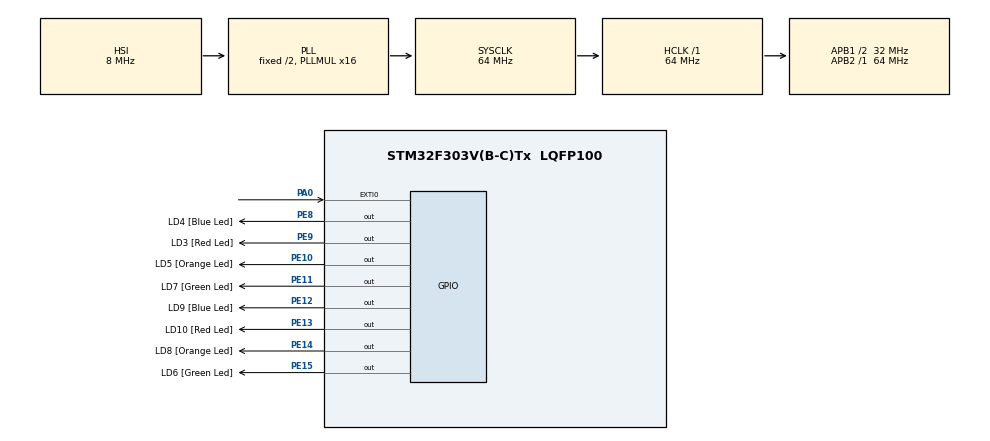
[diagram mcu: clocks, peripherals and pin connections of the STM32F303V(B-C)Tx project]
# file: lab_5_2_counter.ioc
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Mcu.Family=STM32F3
Mcu.Name=STM32F303V(B-C)Tx
Mcu.Package=LQFP100
NVIC.EXTI0_IRQn=true\:0\:0\:false\:false\:true\:true\:true
NVIC.PriorityGroup=NVIC_PRIORITYGROUP_0
PA0.Signal=GPXTI0
PE10.GPIO_Label=LD5 [Orange Led]
PE10.GPIO_ModeDefaultOutputPP=GPIO_MODE_OUTPUT_PP
PE10.GPIO_PuPd=GPIO_NOPULL
PE10.GPIO_Speed=GPIO_SPEED_FREQ_LOW
PE10.Signal=GPIO_Output
PE11.GPIO_Label=LD7 [Green Led]
PE11.GPIO_ModeDefaultOutputPP=GPIO_MODE_OUTPUT_PP
PE11.GPIO_PuPd=GPIO_NOPULL
PE11.GPIO_Speed=GPIO_SPEED_FREQ_LOW
PE11.Signal=GPIO_Output
PE12.GPIO_Label=LD9 [Blue Led]
PE12.GPIO_ModeDefaultOutputPP=GPIO_MODE_OUTPUT_PP
PE12.GPIO_PuPd=GPIO_NOPULL
PE12.GPIO_Speed=GPIO_SPEED_FREQ_LOW
PE12.Signal=GPIO_Output
PE13.GPIO_Label=LD10 [Red Led]
PE13.GPIO_ModeDefaultOutputPP=GPIO_MODE_OUTPUT_PP
PE13.GPIO_PuPd=GPIO_NOPULL
PE13.GPIO_Speed=GPIO_SPEED_FREQ_LOW
PE13.Signal=GPIO_Output
PE14.GPIO_Label=LD8 [Orange Led]
PE14.GPIO_ModeDefaultOutputPP=GPIO_MODE_OUTPUT_PP
PE14.GPIO_PuPd=GPIO_NOPULL
PE14.GPIO_Speed=GPIO_SPEED_FREQ_LOW
PE14.Signal=GPIO_Output
PE15.GPIO_Label=LD6 [Green Led]
PE15.GPIO_ModeDefaultOutputPP=GPIO_MODE_OUTPUT_PP
PE15.GPIO_PuPd=GPIO_NOPULL
PE15.GPIO_Speed=GPIO_SPEED_FREQ_LOW
PE15.Signal=GPIO_Output
PE8.GPIO_Label=LD4 [Blue Led]
PE8.GPIO_ModeDefaultOutputPP=GPIO_MODE_OUTPUT_PP
PE8.GPIO_PuPd=GPIO_NOPULL
PE8.GPIO_Speed=GPIO_SPEED_FREQ_LOW
PE8.Signal=GPIO_Output
PE9.GPIO_Label=LD3 [Red Led]
PE9.GPIO_ModeDefaultOutputPP=GPIO_MODE_OUTPUT_PP
PE9.GPIO_PuPd=GPIO_NOPULL
PE9.GPIO_Speed=GPIO_SPEED_FREQ_LOW
PE9.Signal=GPIO_Output
PF0-OSC_IN.GPIO_Label=OSC_IN
PF0-OSC_IN.Mode=HSE-External-Oscillator
PF0-OSC_IN.Signal=RCC_OSC_IN
PF1-OSC_OUT.Mode=HSE-External-Oscillator
PF1-OSC_OUT.Signal=RCC_OSC_OUT
ProjectManager.HeapSize=0x200
ProjectManager.StackSize=0x400
ProjectManager.TargetToolchain=SW4STM32
RCC.AHBFreq_Value=64000000
RCC.APB1CLKDivider=RCC_HCLK_DIV2
RCC.APB1Freq_Value=32000000
RCC.APB1TimFreq_Value=64000000
RCC.APB2Freq_Value=64000000
RCC.APB2TimFreq_Value=64000000
RCC.CortexFreq_Value=64000000
RCC.HCLKFreq_Value=64000000
RCC.HSE_VALUE=8000000
RCC.HSI_VALUE=8000000
RCC.LSE_VALUE=32768
RCC.PLLMUL=RCC_PLL_MUL16
RCC.SYSCLKFreq_VALUE=64000000
RCC.SYSCLKSourceVirtual=RCC_SYSCLKSOURCE_PLLCLK
RCC.USBFreq_Value=64000000
board=STM32F3DISCOVERY

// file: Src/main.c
/* USER CODE BEGIN Header */
/**
  ******************************************************************************
  * @file           : main.c
  * @brief          : Main program body
  ******************************************************************************
  * @attention
  *
  * <h2><center>&copy; Copyright (c) 2019 STMicroelectronics.
  * All rights reserved.</center></h2>
  *
  * This software component is licensed by ST under BSD 3-Clause license,
  * the "License"; You may not use this file except in compliance with the
  * License. You may obtain a copy of the License at:
  *                        opensource.org/licenses/BSD-3-Clause
  *
  ******************************************************************************
  */
/* USER CODE END Header */

#include "main.h"
#include "gpio.h"

void SystemClock_Config(void);

/* USER CODE BEGIN 0 */
volatile uint8_t count = 0;
/* USER CODE END 0 */

int main(void)
{

  /* MCU Configuration--------------------------------------------------------*/

  /* Reset of all peripherals, Initializes the Flash interface and the Systick. */
  HAL_Init();

  /* Configure the system clock */
  SystemClock_Config();

  /* Initialize all configured peripherals */
  MX_GPIO_Init();
  /* USER CODE BEGIN 2 */
//  HAL_GPIO_ToglePin(GPIOE, GPIO_PIN_8);

  /* USER CODE END 2 */

  /* Infinite loop */
  while (1)
  {

  }
}

void SystemClock_Config(void)
{
  RCC_OscInitTypeDef RCC_OscInitStruct = {0};
  RCC_ClkInitTypeDef RCC_ClkInitStruct = {0};

  /** Initializes the CPU, AHB and APB busses clocks
  */
  RCC_OscInitStruct.OscillatorType = RCC_OSCILLATORTYPE_HSI;
  RCC_OscInitStruct.HSIState = RCC_HSI_ON;
  RCC_OscInitStruct.HSICalibrationValue = RCC_HSICALIBRATION_DEFAULT;
  RCC_OscInitStruct.PLL.PLLState = RCC_PLL_ON;
  RCC_OscInitStruct.PLL.PLLSource = RCC_PLLSOURCE_HSI;
  RCC_OscInitStruct.PLL.PLLMUL = RCC_PLL_MUL16;
  if (HAL_RCC_OscConfig(&RCC_OscInitStruct) != HAL_OK)
  {
    Error_Handler();
  }
  /** Initializes the CPU, AHB and APB busses clocks
  */
  RCC_ClkInitStruct.ClockType = RCC_CLOCKTYPE_HCLK|RCC_CLOCKTYPE_SYSCLK
                              |RCC_CLOCKTYPE_PCLK1|RCC_CLOCKTYPE_PCLK2;
  RCC_ClkInitStruct.SYSCLKSource = RCC_SYSCLKSOURCE_PLLCLK;
  RCC_ClkInitStruct.AHBCLKDivider = RCC_SYSCLK_DIV1;
  RCC_ClkInitStruct.APB1CLKDivider = RCC_HCLK_DIV2;
  RCC_ClkInitStruct.APB2CLKDivider = RCC_HCLK_DIV1;

  if (HAL_RCC_ClockConfig(&RCC_ClkInitStruct, FLASH_LATENCY_2) != HAL_OK)
  {
    Error_Handler();
  }
}

/* USER CODE BEGIN 4 */

void HAL_GPIO_EXTI_Callback(uint16_t GPIO_Pin) {
 if(GPIO_Pin == GPIO_PIN_0)
 {
  static uint32_t last_change_tick;
  if( HAL_GetTick() - last_change_tick < 50 )
  {
   return;
  }
  last_change_tick = HAL_GetTick();
  count += 1;
  GPIOE->ODR &= 0x0F;
  GPIOE->ODR |= count << 8;
 }
}
/* USER CODE END 4 */

void Error_Handler(void)
{
}

/************************ (C) COPYRIGHT STMicroelectronics *****END OF FILE****/
